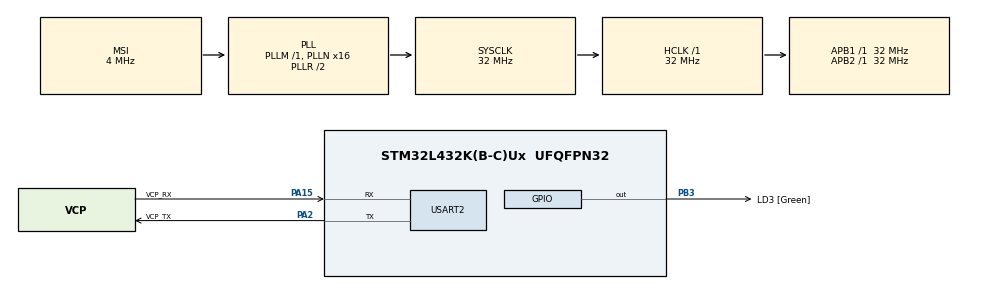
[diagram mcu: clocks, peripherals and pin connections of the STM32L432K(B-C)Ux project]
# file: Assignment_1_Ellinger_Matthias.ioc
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FREERTOS.Tasks01=WorkerTask1,24,128,StartWorkerTask1,Default,NULL,Dynamic,NULL,NULL;WorkerTask2,8,128,StartWorkerTask2,Default,NULL,Dynamic,NULL,NULL;WorkerTask3,8,128,StartWorkerTask3,Default,NULL,Dynamic,NULL,NULL;WatcherTask,8,256,StartWatcherTask,Default,NULL,Dynamic,NULL,NULL
FREERTOS.configTOTAL_HEAP_SIZE=6000
FREERTOS.configUSE_NEWLIB_REENTRANT=1
Mcu.Family=STM32L4
Mcu.Name=STM32L432K(B-C)Ux
Mcu.Package=UFQFPN32
NVIC.PriorityGroup=NVIC_PRIORITYGROUP_4
NVIC.TIM6_DAC_IRQn=true\:15\:0\:false\:false\:true\:false\:false\:true\:true
NVIC.TimeBase=TIM6_DAC_IRQn
NVIC.TimeBaseIP=TIM6
PA0.GPIO_Label=MCO [High speed clock in]
PA0.Mode=HSE-External-Clock-Source-for-LittleOrca
PA0.Signal=RCC_CK_IN
PA13\ (JTMS-SWDIO).GPIO_Label=SWDIO
PA13\ (JTMS-SWDIO).Mode=Serial_Wire
PA13\ (JTMS-SWDIO).Signal=SYS_JTMS-SWDIO
PA14\ (JTCK-SWCLK).GPIO_Label=SWCLK
PA14\ (JTCK-SWCLK).Mode=Serial_Wire
PA14\ (JTCK-SWCLK).Signal=SYS_JTCK-SWCLK
PA15\ (JTDI).GPIO_Label=VCP_RX
PA15\ (JTDI).Mode=Asynchronous
PA15\ (JTDI).Signal=USART2_RX
PA2.GPIO_Label=VCP_TX
PA2.Mode=Asynchronous
PA2.Signal=USART2_TX
PB3\ (JTDO-TRACESWO).GPIO_Label=LD3 [Green]
PB3\ (JTDO-TRACESWO).Signal=GPIO_Output
PC14-OSC32_IN\ (PC14).Mode=LSE-External-Oscillator
PC14-OSC32_IN\ (PC14).Signal=RCC_OSC32_IN
PC15-OSC32_OUT\ (PC15).Mode=LSE-External-Oscillator
PC15-OSC32_OUT\ (PC15).Signal=RCC_OSC32_OUT
ProjectManager.HeapSize=0x200
ProjectManager.StackSize=0x400
ProjectManager.TargetToolchain=STM32CubeIDE
RCC.AHBFreq_Value=32000000
RCC.APB1Freq_Value=32000000
RCC.APB1TimFreq_Value=32000000
RCC.APB2Freq_Value=32000000
RCC.APB2TimFreq_Value=32000000
RCC.CortexFreq_Value=32000000
RCC.HCLKFreq_Value=32000000
RCC.HSE_VALUE=8000000
RCC.HSI16_VALUE=16000000
RCC.HSI48_VALUE=48000000
RCC.HSI_VALUE=16000000
RCC.MSI_VALUE=4000000
RCC.PLLMUL=RCC_PLLMUL_4
RCC.PLLN=16
RCC.SYSCLKFreq_VALUE=32000000
RCC.SYSCLKSource=RCC_SYSCLKSOURCE_PLLCLK
RCC.VCOOutputFreq_Value=64000000
USART2.VirtualMode-Asynchronous=VM_ASYNC
VP_FREERTOS_VS_CMSIS_V2.Mode=CMSIS_V2
VP_SYS_VS_tim6.Mode=TIM6
board=NUCLEO-L432KC

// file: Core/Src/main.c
/* USER CODE BEGIN Header */
/**
  ******************************************************************************
  * @file           : main.c
  * @brief          : Main program body
  ******************************************************************************
  * @attention
  *
  * Copyright (c) 2026 STMicroelectronics.
  * All rights reserved.
  *
  * This software is licensed under terms that can be found in the LICENSE file
  * in the root directory of this software component.
  * If no LICENSE file comes with this software, it is provided AS-IS.
  *
  ******************************************************************************
  */
/* USER CODE END Header */
#include "main.h"
#include "cmsis_os.h"

/* USER CODE BEGIN Includes */
#include <stdio.h>
#include <watcher.h>
#include <worker.h>
/* USER CODE END Includes */

/* USER CODE BEGIN PD */
#define NUMB_WORKER_TASKS 3
#define TASK_1_EXTRA_STACK 200
/* USER CODE END PD */

UART_HandleTypeDef huart2;

/* Definitions for WorkerTask1 */
osThreadId_t WorkerTask1Handle;
const osThreadAttr_t WorkerTask1_attributes = {
  .name = "WorkerTask1",
  .stack_size = 128 * 4,
  .priority = (osPriority_t) osPriorityNormal,
};
/* Definitions for WorkerTask2 */
osThreadId_t WorkerTask2Handle;
const osThreadAttr_t WorkerTask2_attributes = {
  .name = "WorkerTask2",
  .stack_size = 128 * 4,
  .priority = (osPriority_t) osPriorityLow,
};
/* Definitions for WorkerTask3 */
osThreadId_t WorkerTask3Handle;
const osThreadAttr_t WorkerTask3_attributes = {
  .name = "WorkerTask3",
  .stack_size = 128 * 4,
  .priority = (osPriority_t) osPriorityLow,
};
/* Definitions for WatcherTask */
osThreadId_t WatcherTaskHandle;
const osThreadAttr_t WatcherTask_attributes = {
  .name = "WatcherTask",
  .stack_size = 256 * 4,
  .priority = (osPriority_t) osPriorityLow,
};

void SystemClock_Config(void);
static void MX_GPIO_Init(void);
static void MX_USART2_UART_Init(void);
void StartWorkerTask1(void *argument);
void StartWorkerTask2(void *argument);
void StartWorkerTask3(void *argument);
void StartWatcherTask(void *argument);

int main(void)
{

  /* MCU Configuration--------------------------------------------------------*/

  /* Reset of all peripherals, Initializes the Flash interface and the Systick. */
  HAL_Init();

  /* Configure the system clock */
  SystemClock_Config();

  /* Initialize all configured peripherals */
  MX_GPIO_Init();
  MX_USART2_UART_Init();

  /* Init scheduler */
  osKernelInitialize();

  /* Create the thread(s) */
  /* creation of WorkerTask1 */
  WorkerTask1Handle = osThreadNew(StartWorkerTask1, NULL, &WorkerTask1_attributes);

  /* creation of WorkerTask2 */
  WorkerTask2Handle = osThreadNew(StartWorkerTask2, NULL, &WorkerTask2_attributes);

  /* creation of WorkerTask3 */
  WorkerTask3Handle = osThreadNew(StartWorkerTask3, NULL, &WorkerTask3_attributes);

  /* creation of WatcherTask */
  WatcherTaskHandle = osThreadNew(StartWatcherTask, NULL, &WatcherTask_attributes);

  /* Start scheduler */
  osKernelStart();

  /* We should never get here as control is now taken by the scheduler */

  /* Infinite loop */
  while (1)
  {

  }
}

void SystemClock_Config(void)
{
  RCC_OscInitTypeDef RCC_OscInitStruct = {0};
  RCC_ClkInitTypeDef RCC_ClkInitStruct = {0};

  /** Configure the main internal regulator output voltage
  */
  if (HAL_PWREx_ControlVoltageScaling(PWR_REGULATOR_VOLTAGE_SCALE1) != HAL_OK)
  {
    Error_Handler();
  }

  /** Configure LSE Drive Capability
  */
  HAL_PWR_EnableBkUpAccess();
  __HAL_RCC_LSEDRIVE_CONFIG(RCC_LSEDRIVE_LOW);

  /** Initializes the RCC Oscillators according to the specified parameters
  * in the RCC_OscInitTypeDef structure.
  */
  RCC_OscInitStruct.OscillatorType = RCC_OSCILLATORTYPE_LSE|RCC_OSCILLATORTYPE_MSI;
  RCC_OscInitStruct.LSEState = RCC_LSE_ON;
  RCC_OscInitStruct.MSIState = RCC_MSI_ON;
  RCC_OscInitStruct.MSICalibrationValue = 0;
  RCC_OscInitStruct.MSIClockRange = RCC_MSIRANGE_6;
  RCC_OscInitStruct.PLL.PLLState = RCC_PLL_ON;
  RCC_OscInitStruct.PLL.PLLSource = RCC_PLLSOURCE_MSI;
  RCC_OscInitStruct.PLL.PLLM = 1;
  RCC_OscInitStruct.PLL.PLLN = 16;
  RCC_OscInitStruct.PLL.PLLP = RCC_PLLP_DIV7;
  RCC_OscInitStruct.PLL.PLLQ = RCC_PLLQ_DIV2;
  RCC_OscInitStruct.PLL.PLLR = RCC_PLLR_DIV2;
  if (HAL_RCC_OscConfig(&RCC_OscInitStruct) != HAL_OK)
  {
    Error_Handler();
  }

  /** Initializes the CPU, AHB and APB buses clocks
  */
  RCC_ClkInitStruct.ClockType = RCC_CLOCKTYPE_HCLK|RCC_CLOCKTYPE_SYSCLK
                              |RCC_CLOCKTYPE_PCLK1|RCC_CLOCKTYPE_PCLK2;
  RCC_ClkInitStruct.SYSCLKSource = RCC_SYSCLKSOURCE_PLLCLK;
  RCC_ClkInitStruct.AHBCLKDivider = RCC_SYSCLK_DIV1;
  RCC_ClkInitStruct.APB1CLKDivider = RCC_HCLK_DIV1;
  RCC_ClkInitStruct.APB2CLKDivider = RCC_HCLK_DIV1;

  if (HAL_RCC_ClockConfig(&RCC_ClkInitStruct, FLASH_LATENCY_1) != HAL_OK)
  {
    Error_Handler();
  }

  /** Enable MSI Auto calibration
  */
  HAL_RCCEx_EnableMSIPLLMode();
}

static void MX_USART2_UART_Init(void)
{

  huart2.Instance = USART2;
  huart2.Init.BaudRate = 115200;
  huart2.Init.WordLength = UART_WORDLENGTH_8B;
  huart2.Init.StopBits = UART_STOPBITS_1;
  huart2.Init.Parity = UART_PARITY_NONE;
  huart2.Init.Mode = UART_MODE_TX_RX;
  huart2.Init.HwFlowCtl = UART_HWCONTROL_NONE;
  huart2.Init.OverSampling = UART_OVERSAMPLING_16;
  huart2.Init.OneBitSampling = UART_ONE_BIT_SAMPLE_DISABLE;
  huart2.AdvancedInit.AdvFeatureInit = UART_ADVFEATURE_NO_INIT;
  if (HAL_UART_Init(&huart2) != HAL_OK)
  {
    Error_Handler();
  }

}

static void MX_GPIO_Init(void)
{
  GPIO_InitTypeDef GPIO_InitStruct = {0};

  /* GPIO Ports Clock Enable */
  __HAL_RCC_GPIOC_CLK_ENABLE();
  __HAL_RCC_GPIOA_CLK_ENABLE();
  __HAL_RCC_GPIOB_CLK_ENABLE();

  /*Configure GPIO pin Output Level */
  HAL_GPIO_WritePin(LD3_GPIO_Port, LD3_Pin, GPIO_PIN_RESET);

  /*Configure GPIO pin : LD3_Pin */
  GPIO_InitStruct.Pin = LD3_Pin;
  GPIO_InitStruct.Mode = GPIO_MODE_OUTPUT_PP;
  GPIO_InitStruct.Pull = GPIO_NOPULL;
  GPIO_InitStruct.Speed = GPIO_SPEED_FREQ_LOW;
  HAL_GPIO_Init(LD3_GPIO_Port, &GPIO_InitStruct);

}

void StartWorkerTask1(void *argument)
{
  /* USER CODE BEGIN 5 */
    uint8_t extra_stack_use[TASK_1_EXTRA_STACK];
    UNUSED(extra_stack_use);
  /* Infinite loop */
  for(;;)
  {
    osDelay(100);
  }
  osThreadTerminate(NULL);
  /* USER CODE END 5 */
}

void StartWorkerTask2(void *argument)
{
  /* USER CODE BEGIN StartWorkerTask2 */
    uint8_t extra_stack_use[100];
    UNUSED(extra_stack_use);
  /* Infinite loop */
  for(;;)
  {
	recursive_factorial(10);
    osDelay(100);
  }
  osThreadTerminate(NULL);
  /* USER CODE END StartWorkerTask2 */
}

void StartWorkerTask3(void *argument)
{
  /* USER CODE BEGIN StartWorkerTask3 */
    uint8_t extra_stack_use[15];
    UNUSED(extra_stack_use);
  /* Infinite loop */
  for(;;)
  {
	  recursive_factorial(19);
	  osDelay(100);
  }
  osThreadTerminate(NULL);
  /* USER CODE END StartWorkerTask3 */
}

void StartWatcherTask(void *argument)
{
  /* USER CODE BEGIN StartWatcherTask */

	osThreadAttr_t 	thread_attribute	[NUMB_WORKER_TASKS]			= {WorkerTask1_attributes, WorkerTask2_attributes, WorkerTask3_attributes};
	osThreadId_t 	thread_id			[NUMB_WORKER_TASKS] 		= {WorkerTask1Handle, WorkerTask2Handle, WorkerTask3Handle};
  	uint32_t 		free_stack_size		[NUMB_WORKER_TASKS] 		= {0, 0, 0};

  /* Infinite loop */
  for(;;)
  {

	  get_stack_size	(thread_id		, free_stack_size,	 NUMB_WORKER_TASKS);
	  print_stack_size	(free_stack_size, thread_attribute,	 NUMB_WORKER_TASKS, huart2);
	  osDelay	(500);
  }
  osThreadTerminate(NULL);
  /* USER CODE END StartWatcherTask */
}

void HAL_TIM_PeriodElapsedCallback(TIM_HandleTypeDef *htim)
{
  if (htim->Instance == TIM6)
  {
    HAL_IncTick();
  }
}

void Error_Handler(void)
{
  __disable_irq();
  while (1)
  {
  }
}
